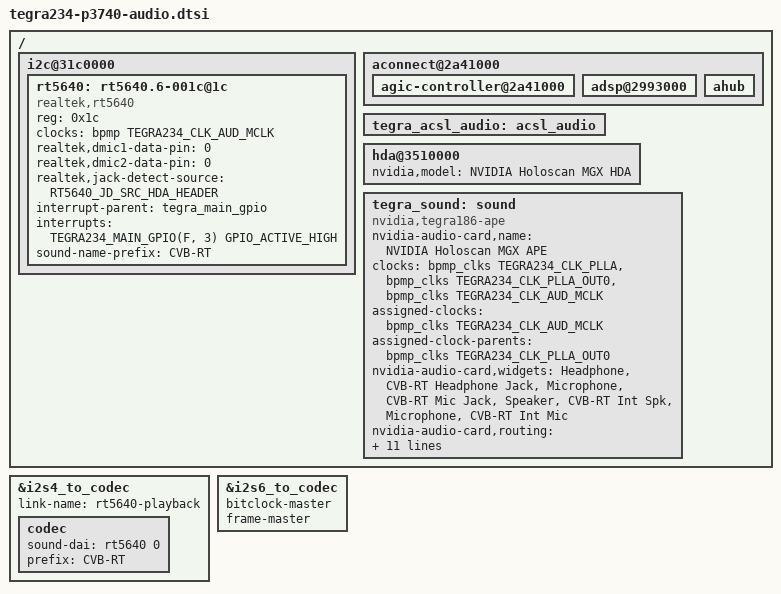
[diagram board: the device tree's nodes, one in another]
/*
 * T234 p3740 audio DTSI file.
 *
 * Copyright (c) 2021, NVIDIA CORPORATION.  All rights reserved.
 *
 * This program is free software; you can redistribute it and/or modify
 * it under the terms of the GNU General Public License as published by
 * the Free Software Foundation; version 2 of the License.
 *
 * This program is distributed in the hope that it will be useful, but WITHOUT
 * ANY WARRANTY; without even the implied warranty of MERCHANTABILITY or
 * FITNESS FOR A PARTICULAR PURPOSE.  See the GNU General Public License for
 * more details.
 */

#include <audio/tegra-platforms-audio-dai-links.dtsi>
#include <audio/tegra186-audio-dai-links.dtsi>
#include <dt-bindings/sound/rt5640.h>
#include <dt-bindings/gpio/tegra234-gpio.h>
#include <dt-bindings/audio/tegra234-audio.h>

/ {
	i2c@31c0000 {
		rt5640: rt5640.6-001c@1c {
			compatible = "realtek,rt5640";
			reg = <0x1c>;

			clocks = <&bpmp TEGRA234_CLK_AUD_MCLK>;
			clock-names = "mclk";

			realtek,dmic1-data-pin = <0>; /* RT5640_DMIC1_NULL */
			realtek,dmic2-data-pin = <0>; /* RT5640_DMIC2_NULL */
			realtek,jack-detect-source = <RT5640_JD_SRC_HDA_HEADER>;

			/* Codec IRQ output */
			interrupt-parent = <&tegra_main_gpio>;
			interrupts = <TEGRA234_MAIN_GPIO(F, 3) GPIO_ACTIVE_HIGH>;

			#sound-dai-cells = <1>;
			sound-name-prefix = "CVB-RT";

			status = "okay";
		};
	};

	aconnect@2a41000 {
		status = "okay";

		agic-controller@2a41000 {
			status = "okay";
		};

		adsp@2993000 {
			status = "okay";
		};

		ahub {
			status = "okay";
		};
	};

	tegra_acsl_audio: acsl_audio {
		status = "okay";
	};

	hda@3510000 {
		nvidia,model = "NVIDIA Holoscan MGX HDA";
		status = "okay";
	};

	tegra_sound: sound {
		status = "okay";
		compatible = "nvidia,tegra186-ape";
		nvidia-audio-card,name = "NVIDIA Holoscan MGX APE";
		clocks = <&bpmp_clks TEGRA234_CLK_PLLA>,
			 <&bpmp_clks TEGRA234_CLK_PLLA_OUT0>,
			 <&bpmp_clks TEGRA234_CLK_AUD_MCLK>;
		clock-names = "pll_a", "pll_a_out0", "extern1";
		assigned-clocks = <&bpmp_clks TEGRA234_CLK_AUD_MCLK>;
		assigned-clock-parents = <&bpmp_clks TEGRA234_CLK_PLLA_OUT0>;

		nvidia-audio-card,widgets =
			"Headphone",    "CVB-RT Headphone Jack",
			"Microphone",   "CVB-RT Mic Jack",
			"Speaker",      "CVB-RT Int Spk",
			"Microphone",   "CVB-RT Int Mic";

		nvidia-audio-card,routing =
			"CVB-RT Headphone Jack",     "CVB-RT HPOL",
			"CVB-RT Headphone Jack",     "CVB-RT HPOR",
			"CVB-RT IN1P",               "CVB-RT Mic Jack",
			"CVB-RT IN2P",               "CVB-RT Mic Jack",
			"CVB-RT IN2N",               "CVB-RT Mic Jack",
			"CVB-RT IN3P",               "CVB-RT Mic Jack",
			"CVB-RT Int Spk",            "CVB-RT SPOLP",
			"CVB-RT Int Spk",            "CVB-RT SPORP",
			"CVB-RT Int Spk",            "CVB-RT LOUTL",
			"CVB-RT Int Spk",            "CVB-RT LOUTR",
			"CVB-RT DMIC1",              "CVB-RT Int Mic",
			"CVB-RT DMIC2",              "CVB-RT Int Mic";

		nvidia-audio-card,mclk-fs = <256>;
	};
};

/*
 * Default config for all I2S dai links are
 * format = "i2s", bitclock-slave, frame-slave,
 * bitclock-noninversion, frame-noninversion,
 * Any change from default needs override on
 * platform specific files.
 */

&i2s4_to_codec {
	link-name = "rt5640-playback";
	codec {
		sound-dai = <&rt5640 0>;
		prefix = "CVB-RT";
	};
};

/* I2S link on CSI Connector */
csi_conn_i2s: &i2s6_to_codec {
	/*
	 * HDMI IN board P3785 for HDMI->CSI I2S signals.
	 */
	bitclock-master;
	frame-master;
};
